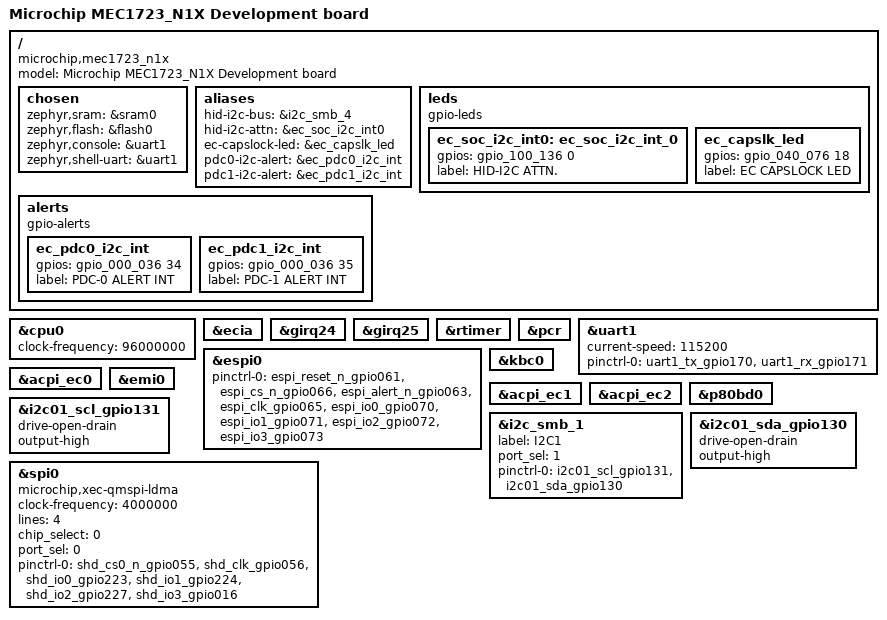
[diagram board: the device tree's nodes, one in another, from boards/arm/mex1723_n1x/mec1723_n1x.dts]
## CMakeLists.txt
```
# SPDX-License-Identifier: Apache-2.0

cmake_minimum_required(VERSION 3.20.0)

list(APPEND EXTRA_ZEPHYR_MODULES
  ${CMAKE_CURRENT_SOURCE_DIR}/../../modules
)

find_package(Zephyr REQUIRED HINTS $ENV{ZEPHYR_BASE})
project(ec_fw)


include_directories(app PRIVATE ${CMAKE_CURRENT_SOURCE_DIR})

add_subdirectory(drivers)
add_subdirectory(services)

target_sources(app PRIVATE main.c)
```

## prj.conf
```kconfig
# nothing here

CONFIG_GPIO=y
CONFIG_PWM=y
CONFIG_I2C=y
CONFIG_SENSOR=y

CONFIG_SENSOR_TMP451=y

CONFIG_LOG=y

CONFIG_SHELL=y
CONFIG_GPIO_SHELL=y
CONFIG_PWM_SHELL=y
CONFIG_I2C_SHELL=y

CONFIG_APP_EVENT_MANAGER=y
```

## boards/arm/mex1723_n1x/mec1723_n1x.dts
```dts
/*
 * Copyright (c) 2024, Microchip Technology Inc.
 *
 * SPDX-License-Identifier: Apache-2.0
 */

/dts-v1/;

#include <microchip/mec172xnsz.dtsi>
#include <microchip/mec172x/mec172xnsz-pinctrl.dtsi>

/ {
	model = "Microchip MEC1723_N1X Development board";
	compatible = "microchip,mec1723_n1x", "microchip,mec172xnsz";

	chosen {
		zephyr,sram = &sram0;
		zephyr,flash = &flash0;
		zephyr,console = &uart1;
		zephyr,shell-uart = &uart1;
	};

	aliases {
		/*
		led0 = &led4;
		led1 = &led3;
		i2c0 = &i2c_smb_0;
		i2c-0 = &i2c_smb_0;
		i2c1 = &i2c_smb_1;
		i2c7 = &i2c_smb_2;
		 */
		hid-i2c-bus = &i2c_smb_4;
		hid-i2c-attn = &ec_soc_i2c_int0;
		ec-capslock-led = &ec_capslk_led;
		pdc0-i2c-alert = &ec_pdc0_i2c_int;
		pdc1-i2c-alert = &ec_pdc1_i2c_int;
	};
	leds {
		compatible = "gpio-leds";
		ec_soc_i2c_int0: ec_soc_i2c_int_0 {
			gpios = <&gpio_100_136 0 GPIO_ACTIVE_HIGH>;
			label = "HID-I2C ATTN.";
		};
		ec_capslk_led: ec_capslk_led {
			gpios = <&gpio_040_076 18 GPIO_ACTIVE_HIGH>;
			label = "EC CAPSLOCK LED";
		};
	};
	alerts {
		compatible = "gpio-alerts";
		ec_pdc0_i2c_int: ec_pdc0_i2c_int {
			gpios = <&gpio_000_036 34 GPIO_ACTIVE_HIGH>;
			label = "PDC-0 ALERT INT";
		};
		ec_pdc1_i2c_int: ec_pdc1_i2c_int {
			gpios = <&gpio_000_036 35 GPIO_ACTIVE_HIGH>;
			label = "PDC-1 ALERT INT";
		};
	};
};

&cpu0 {
	clock-frequency = <96000000>;
	status = "okay";
};

/* Initialize ECIA. Does not initialize child devices */
&ecia {
	status = "okay";
};

/* Enable aggregated GIRQ24 and GIRQ25 for eSPI virtual wires interrupts */
&girq24 {
	status = "okay";
};

&girq25 {
	status = "okay";
};

&rtimer {
	status = "okay";
};

&pcr {
	status = "okay";
};

&uart1 {
	status = "okay";
	current-speed = <115200>;
	pinctrl-0 = <&uart1_tx_gpio170 &uart1_rx_gpio171>;
	pinctrl-names = "default";
};

/*
&adc0 {
	status = "okay";
	pinctrl-0 = <&adc00_gpio200 &adc03_gpio203
		     &adc04_gpio204 &adc05_gpio205>;
	pinctrl-names = "default";
};
*/

&espi0 {
	status = "okay";
	pinctrl-0 = < &espi_reset_n_gpio061 &espi_cs_n_gpio066
		      &espi_alert_n_gpio063 &espi_clk_gpio065
		      &espi_io0_gpio070 &espi_io1_gpio071
		      &espi_io2_gpio072 &espi_io3_gpio073 >;
	pinctrl-names = "default";
};

/* enable various eSPI child devices (host facing) */
&kbc0 {
	status = "okay";
};

&acpi_ec0 {
	status = "okay";
};

&acpi_ec1 {
	status = "okay";
};

&acpi_ec2 {
	status = "okay";
};

&emi0 {
	status = "okay";
};

&p80bd0 {
	status = "okay";
};

/* I2C */
/*
&i2c_smb_0 {
	status = "okay";
	label = "I2C0";
	port_sel = <0>;

	pinctrl-0 = < &i2c00_scl_gpio004 &i2c00_sda_gpio003 >;
	pinctrl-names = "default";
};

&i2c00_scl_gpio004 {
	drive-open-drain;
	output-high;
};

&i2c00_sda_gpio003 {
	drive-open-drain;
	output-high;
};
*/
&i2c_smb_1 {
	status = "okay";
	label = "I2C1";
	port_sel = <1>;
	pinctrl-0 = <&i2c01_scl_gpio131 &i2c01_sda_gpio130>;
	pinctrl-names = "default";
};

&i2c01_scl_gpio131 {
	drive-open-drain;
	output-high;
};

&i2c01_sda_gpio130 {
	drive-open-drain;
	output-high;
};
/*
&i2c_smb_2 {
	status = "okay";
	label = "I2C7";
	port_sel = <7>;
	pinctrl-0 = <&i2c07_scl_gpio013 &i2c07_sda_gpio012>;
	pinctrl-names = "default";
};

&i2c07_scl_gpio013 {
	drive-open-drain;
	output-high;
};

&i2c07_sda_gpio012 {
	drive-open-drain;
	output-high;
};
*/

&spi0 {
	compatible = "microchip,xec-qmspi-ldma";
	status = "okay";
	clock-frequency = <4000000>;
	lines = <4>;
	chip_select = <0>;
	port_sel = <0>; /* Shared SPI */

	pinctrl-0 = < &shd_cs0_n_gpio055
		      &shd_clk_gpio056
		      &shd_io0_gpio223
		      &shd_io1_gpio224
		      &shd_io2_gpio227
		      &shd_io3_gpio016 >;
	pinctrl-names = "default";
};

/*
&kscan0 {
	status = "okay";

	pinctrl-0 = < &ksi0_gpio017
		      &ksi1_gpio020
		      &ksi2_gpio021
		      &ksi3_gpio026
		      &ksi4_gpio027
		      &ksi5_gpio030
		      &ksi6_gpio031
		      &ksi7_gpio032
		      &kso00_gpio040
		      &kso01_gpio045
		      &kso02_gpio046
		      &kso03_gpio047
		      &kso04_gpio107
		      &kso05_gpio112
		      &kso06_gpio113
		      &kso07_gpio120
		      &kso08_gpio121
		      &kso09_gpio122
		      &kso10_gpio123
		      &kso11_gpio124
		      &kso12_gpio125
		      &kso13_gpio126 >;
	pinctrl-names = "default";
};
*/
```

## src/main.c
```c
/*
 * Copyright (c) 2012-2014 Wind River Systems, Inc.
 *
 * SPDX-License-Identifier: Apache-2.0
 */

#include <zephyr/kernel.h>

int main(void)
{
	printk("Hello World! %s, Rev: %s\n", CONFIG_BOARD, CONFIG_BOARD_REVISION);
	return 0;
}
```

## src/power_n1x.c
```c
/*
 * @Author: andy.chang
 * @Date: 2025-06-29 17:06:01
 * @Last Modified by: andy.chang
 * @Last Modified time: 2025-06-29 19:32:50
 */

#include <errno.h>
#include <zephyr/drivers/gpio.h>
#include <zephyr/kernel.h>
#include <zephyr/logging/log.h>


LOG_MODULE_REGISTER(pwr_n1x, LOG_LEVEL_INFO);

#define MCHP_GPIO_DECLARE(PIN_DT)                                              \
    static const struct gpio_dt_spec PIN_DT =                                  \
        GPIO_DT_SPEC_GET(DT_NODELABEL(PIN_DT), gpios)

#define MCHP_GPIO_SET(PIN, LEVEL)                                              \
    do {                                                                       \
        LOG_INF("Drive %s %s", #PIN, (LEVEL) ? "high" : "low");                \
        int ret = gpio_pin_set_dt(PIN, LEVEL);                                 \
        if (ret) {                                                             \
            LOG_ERR("Failed to write %s", #PIN);                               \
            return ret;                                                        \
        }                                                                      \
    } while (0)

#define MCHP_GPIO_WAIT(PIN, LEVEL)                                             \
    do {                                                                       \
        LOG_INF("Wait %s %s", #PIN, (LEVEL) ? "high" : "low");                 \
        do {                                                                   \
            int ret = gpio_pin_get_dt(PIN);                                    \
            if (ret < 0) {                                                     \
                LOG_ERR("Failed to wait %s", #PIN);                            \
                return ret;                                                    \
            } else if (ret == LEVEL) {                                         \
                break;                                                         \
            }                                                                  \
            k_sleep(K_USEC(100));                                              \
        } while (1);                                                           \
    } while (0)

MCHP_GPIO_DECLARE(ao_3v3_1v8_1v2_en);
MCHP_GPIO_DECLARE(ao_1v8_1v2_pg);
MCHP_GPIO_DECLARE(ao_5v_en);
MCHP_GPIO_DECLARE(ao_pr3v3_en);
MCHP_GPIO_DECLARE(ao_5v_pg);
MCHP_GPIO_DECLARE(ao_pr3v3_pg);
MCHP_GPIO_DECLARE(pmic_en);
MCHP_GPIO_DECLARE(vusb_5v_tpc_pg);
MCHP_GPIO_DECLARE(vio12_usb2_vdd1_en);
MCHP_GPIO_DECLARE(vio12_usb2_vdd1_pg);
MCHP_GPIO_DECLARE(gpu_vr_pg);
MCHP_GPIO_DECLARE(vio18_vdd2l_en);
MCHP_GPIO_DECLARE(vio18_vdd2l_pg);
MCHP_GPIO_DECLARE(pmic_pg);
MCHP_GPIO_DECLARE(pmic_rsmrst);
#ifndef CONFIG_MEC1723_N1X_D_P
MCHP_GPIO_DECLARE(dp12v_en);
MCHP_GPIO_DECLARE(drvvbus_en);
#endif
MCHP_GPIO_DECLARE(vqps_ext_en);
MCHP_GPIO_DECLARE(ovrm_en);
MCHP_GPIO_DECLARE(vtr2_thermtrip);

static int power_on(void);
static int power_off(void);
static int _power_off(k_timeout_t delay);

static int power_on(void) {
    int ret;

    LOG_WRN("Run power on sequence: %s", CONFIG_BOARD);

    // ---------------------------------------------
    MCHP_GPIO_SET(&ao_3v3_1v8_1v2_en, 1);
    MCHP_GPIO_WAIT(&ao_1v8_1v2_pg, 1);

    // ---------------------------------------------
    MCHP_GPIO_SET(&ao_5v_en, 1);
    MCHP_GPIO_SET(&ao_pr3v3_en, 1);

    MCHP_GPIO_WAIT(&ao_5v_pg, 1);
    MCHP_GPIO_WAIT(&ao_pr3v3_pg, 1);

    // ---------------------------------------------
    // Check PMIC version before enable PMIC
    // MCHP_GPIO_SET(EC_PMIC_EN_N, 1);
    // LOG_DBG("before PMIC_update, EC_PMIC_EN_N=%d",
    // gpio_read_pin(EC_PMIC_EN_N)); check_PMIC_prog_status(PMIC0_ADDR,
    // Program_PMIC0); check_PMIC_prog_status(PMIC1_ADDR, Program_PMIC1);

    LOG_INF("Enable PMIC");
    MCHP_GPIO_SET(&pmic_en, 0);

    // ---------------------------------------------
    MCHP_GPIO_WAIT(&vusb_5v_tpc_pg, 1);

    // ---------------------------------------------
    MCHP_GPIO_WAIT(&vio12_usb2_vdd1_en, 1);
    MCHP_GPIO_WAIT(&vio12_usb2_vdd1_pg, 1);
    MCHP_GPIO_WAIT(&gpu_vr_pg, 1);
    MCHP_GPIO_WAIT(&vio18_vdd2l_en, 1);
    MCHP_GPIO_WAIT(&vio18_vdd2l_pg, 1);

    // ---------------------------------------------
    MCHP_GPIO_WAIT(&pmic_pg, 1);

    MCHP_GPIO_SET(&pmic_rsmrst, 1);
    // k_work_reschedule(&ec_boot_wd_work, K_SECONDS(1));
    // LOG_INF("%s k_work_reschedule ec_boot_wd_work", __func__);
    MCHP_GPIO_SET(&pmic_en, 1);
    // pwr_err_thread_enable(true);
    // LOG_INF("%s enable power error handler", __func__);
    // ---------------------------------------------
    // EC eSPI initialization
#ifndef CONFIG_MEC1723_N1X_D_P
    MCHP_GPIO_SET(&dp12v_en, 1);
    MCHP_GPIO_SET(&drvvbus_en, 1);
#endif
    MCHP_GPIO_SET(&vqps_ext_en, 1);
    MCHP_GPIO_SET(&ovrm_en, 0);

    // espihub_add_state_handler(pwrseq_slp_handler);
    // espihub_add_warn_handler(ESPIHUB_SUSPEND_WARNING, pwrseq_sus_handler);
    // espihub_add_warn_handler(ESPIHUB_BUS_RESET, espi_bus_reset_handler);

    LOG_WRN("Power sequence Finish!");

    return ret;
}

static int power_off(void) {
    int ret = 0;

    LOG_WRN("%s start", __func__);

    // Pull down THERMTRIP_N -> Wait 300us -> Pull up THERMTRIP_N
    gpio_pin_configure_dt(&vtr2_thermtrip, GPIO_OUTPUT_LOW | GPIO_OPEN_DRAIN);
    k_sleep(K_USEC(300));
    gpio_pin_configure_dt(&vtr2_thermtrip, GPIO_INPUT | GPIO_INT_EDGE_FALLING);

    // Wait 100ms
    k_sleep(K_MSEC(100));

	// Same as "_power_off"
	_power_off(K_MSEC(0));

    LOG_WRN("%s end", __func__);
    return ret;
}

static int _power_off(k_timeout_t delay) {
    int ret = 0;

    /* 2: wait EC_PMIC_PWR_GD low */
    MCHP_GPIO_WAIT(&pmic_pg, 0);

    /* 4: drive VTR3_SYSRSTB low */
    MCHP_GPIO_SET(&pmic_rsmrst, 0);

#ifndef CONFIG_MEC1723_N1X_D_P
	k_sleep(delay);
    /* 5: write EC_DP12V_EN low */
    MCHP_GPIO_SET(&dp12v_en, 0);

    /* 6: write EC_DRVVBUS_EN low */
    MCHP_GPIO_SET(&drvvbus_en, 0);
#endif

    /* 7: write EC_VQPS_EXT_EN low */
    MCHP_GPIO_SET(&vqps_ext_en, 0);

	/* 8: write EC_OVRM_EN_N high to disable */
	MCHP_GPIO_SET(&ovrm_en, 1);
	
    /* 9: drive EC_AOVCC5V_EN low */
    MCHP_GPIO_SET(&ao_5v_en, 0);

    /* 10: write EC_PR3V3_EN low */
    MCHP_GPIO_SET(&ao_pr3v3_en, 0);

    /* 11: wait EC_AOVCC5V_PG low */
    MCHP_GPIO_WAIT(&ao_5v_pg, 0);

    /* 12: wait EC_VUSB_5V_TPC_PG low */
    MCHP_GPIO_WAIT(&vusb_5v_tpc_pg, 0);

    /* 13: wait EC_PR3V3_PG low */
    MCHP_GPIO_WAIT(&ao_pr3v3_pg, 0);

    /* 14: wait VIO_12_USB2_VDD1_EN low */
    MCHP_GPIO_WAIT(&vio12_usb2_vdd1_en, 0);

    /* 15: wait EC_VIO_12_USB2_VDD1_PG low */
    MCHP_GPIO_WAIT(&vio12_usb2_vdd1_pg, 0);

    /* 16: wait GPU_VR_PGOOD low */
    MCHP_GPIO_WAIT(&gpu_vr_pg, 0);

    /* 17: wait VIO_18_VDD2L_EN low */
    MCHP_GPIO_WAIT(&vio18_vdd2l_en, 0);

    /* 18: wait EC_VIO_18_VDD2L_PG low */
    MCHP_GPIO_WAIT(&vio18_vdd2l_pg, 0);

    /* 19: drive EC_AO_3V3_1V8_1V2_EN low */
    MCHP_GPIO_SET(&ao_3v3_1v8_1v2_en, 0);

    /* 20: wait EC_AO1V8_AO1V2_PG low */
    MCHP_GPIO_WAIT(&ao_1v8_1v2_pg, 0);

    return ret;
}
```

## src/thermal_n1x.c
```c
/*
 * @Author: andy.chang
 * @Date: 2025-06-29 17:06:01
 * @Last Modified by: andy.chang
 * @Last Modified time: 2025-06-29 21:35:50
 */

#include <errno.h>
#include <zephyr/drivers/pwm.h>
#include <zephyr/kernel.h>
#include <zephyr/logging/log.h>


LOG_MODULE_REGISTER(ther_n1x, LOG_LEVEL_INF);

static const struct device *fan_devs[] = {
    DEVICE_DT_GET(DT_NODELABEL(pwm0)),
    DEVICE_DT_GET(DT_NODELABEL(pwm1)),
};

static const struct device *tach_devs[] = {
    DEVICE_DT_GET(DT_NODELABEL(tach0)),
    DEVICE_DT_GET(DT_NODELABEL(tach1)),
};

// static const struct device *tach_dev[TACH_DEV_LIST_SIZE];

#include <zephyr/init.h>

static int init_config(void) {
    int ret = 0;

    LOG_INF("Initializing thermal configuration...");

    for (size_t i = 0; i < ARRAY_SIZE(fan_devs); i++) {
        if (!device_is_ready(fan_devs[i])) {
            LOG_ERR("fan%d not ready", i);
            return -ENODEV;
        }

        // Set the PWM period for each fan device
        ret = pwm_set(fan_devs[i], 0, PWM_USEC(25), PWM_USEC(25),
                      PWM_POLARITY_INVERTED);
        if (ret < 0) {
            LOG_ERR("Failed to set PWM cycles for fan%d: %d", i, ret);
            return ret;
        }
    }

    return ret;
}

SYS_INIT(init_config, APPLICATION, 0);
```
